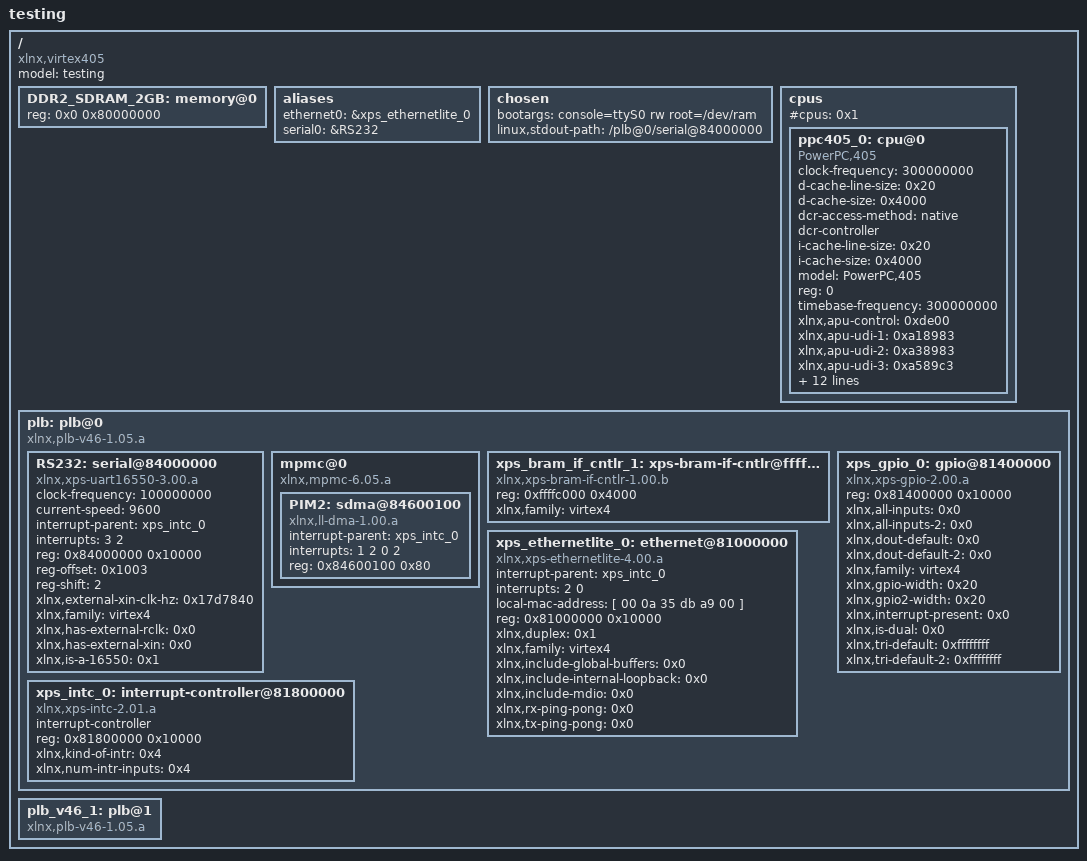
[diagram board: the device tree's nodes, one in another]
/*
 * Device Tree Generator version: 1.3
 *
 * (C) Copyright 2007-2008 Xilinx, Inc.
 * (C) Copyright 2007-2009 Michal Simek
 *
 * Michal SIMEK <monstr@monstr.eu>
 *
 * This program is free software; you can redistribute it and/or
 * modify it under the terms of the GNU General Public License as
 * published by the Free Software Foundation; either version 2 of
 * the License, or (at your option) any later version.
 *
 * This program is distributed in the hope that it will be useful,
 * but WITHOUT ANY WARRANTY; without even the implied warranty of
 * MERCHANTABILITY or FITNESS FOR A PARTICULAR PURPOSE. See the
 * GNU General Public License for more details.
 *
 * You should have received a copy of the GNU General Public License
 * along with this program; if not, write to the Free Software
 * Foundation, Inc., 59 Temple Place, Suite 330, Boston,
 * MA 02111-1307 USA
 *
 * CAUTION: This file is automatically generated by libgen.
 * Version: Xilinx EDK 13.3 EDK_O.76xd
 *
 * XPS project directory: device-tree_bsp_2
 */

/dts-v1/;
/ {
	#address-cells = <1>;
	#size-cells = <1>;
	compatible = "xlnx,virtex405", "xlnx,virtex";
	model = "testing";
	DDR2_SDRAM_2GB: memory@0 {
		device_type = "memory";
		reg = < 0x0 0x80000000 >;
	} ;
	aliases {
		ethernet0 = &xps_ethernetlite_0;
		serial0 = &RS232;
	} ;
	chosen {
		bootargs = "console=ttyS0 rw root=/dev/ram";
		linux,stdout-path = "/plb@0/serial@84000000";
	} ;
	cpus {
		#address-cells = <1>;
		#cpus = <0x1>;
		#size-cells = <0>;
		ppc405_0: cpu@0 {
			clock-frequency = <300000000>;
			compatible = "PowerPC,405", "ibm,ppc405";
			d-cache-line-size = <0x20>;
			d-cache-size = <0x4000>;
			dcr-access-method = "native";
			dcr-controller ;
			device_type = "cpu";
			i-cache-line-size = <0x20>;
			i-cache-size = <0x4000>;
			model = "PowerPC,405";
			reg = <0>;
			timebase-frequency = <300000000>;
			xlnx,apu-control = <0xde00>;
			xlnx,apu-udi-1 = <0xa18983>;
			xlnx,apu-udi-2 = <0xa38983>;
			xlnx,apu-udi-3 = <0xa589c3>;
			xlnx,apu-udi-4 = <0xa789c3>;
			xlnx,apu-udi-5 = <0xa98c03>;
			xlnx,apu-udi-6 = <0xab8c03>;
			xlnx,apu-udi-7 = <0xad8c43>;
			xlnx,apu-udi-8 = <0xaf8c43>;
			xlnx,deterministic-mult = <0x0>;
			xlnx,disable-operand-forwarding = <0x1>;
			xlnx,fastest-plb-clock = "DPLB0";
			xlnx,generate-plb-timespecs = <0x1>;
			xlnx,mmu-enable = <0x1>;
			xlnx,pvr-high = <0x0>;
			xlnx,pvr-low = <0x0>;
		} ;
	} ;
	plb: plb@0 {
		#address-cells = <1>;
		#size-cells = <1>;
		compatible = "xlnx,plb-v46-1.05.a", "xlnx,plb-v46-1.00.a", "simple-bus";
		ranges ;
		RS232: serial@84000000 {
			clock-frequency = <100000000>;
			compatible = "xlnx,xps-uart16550-3.00.a", "ns16550";
			current-speed = <9600>;
			device_type = "serial";
			interrupt-parent = <&xps_intc_0>;
			interrupts = < 3 2 >;
			reg = < 0x84000000 0x10000 >;
			reg-offset = <0x1003>;
			reg-shift = <2>;
			xlnx,external-xin-clk-hz = <0x17d7840>;
			xlnx,family = "virtex4";
			xlnx,has-external-rclk = <0x0>;
			xlnx,has-external-xin = <0x0>;
			xlnx,is-a-16550 = <0x1>;
		} ;
		mpmc@0 {
			#address-cells = <1>;
			#size-cells = <1>;
			compatible = "xlnx,mpmc-6.05.a";
			ranges ;
			PIM2: sdma@84600100 {
				compatible = "xlnx,ll-dma-1.00.a";
				interrupt-parent = <&xps_intc_0>;
				interrupts = < 1 2 0 2 >;
				reg = < 0x84600100 0x80 >;
			} ;
		} ;
		xps_bram_if_cntlr_1: xps-bram-if-cntlr@ffffc000 {
			compatible = "xlnx,xps-bram-if-cntlr-1.00.b", "xlnx,xps-bram-if-cntlr-1.00.a";
			reg = < 0xffffc000 0x4000 >;
			xlnx,family = "virtex4";
		} ;
		xps_ethernetlite_0: ethernet@81000000 {
			compatible = "xlnx,xps-ethernetlite-4.00.a", "xlnx,xps-ethernetlite-1.00.a";
			device_type = "network";
			interrupt-parent = <&xps_intc_0>;
			interrupts = < 2 0 >;
			local-mac-address = [ 00 0a 35 db a9 00 ];
			reg = < 0x81000000 0x10000 >;
			xlnx,duplex = <0x1>;
			xlnx,family = "virtex4";
			xlnx,include-global-buffers = <0x0>;
			xlnx,include-internal-loopback = <0x0>;
			xlnx,include-mdio = <0x0>;
			xlnx,rx-ping-pong = <0x0>;
			xlnx,tx-ping-pong = <0x0>;
		} ;
		xps_gpio_0: gpio@81400000 {
			compatible = "xlnx,xps-gpio-2.00.a", "xlnx,xps-gpio-1.00.a";
			reg = < 0x81400000 0x10000 >;
			xlnx,all-inputs = <0x0>;
			xlnx,all-inputs-2 = <0x0>;
			xlnx,dout-default = <0x0>;
			xlnx,dout-default-2 = <0x0>;
			xlnx,family = "virtex4";
			xlnx,gpio-width = <0x20>;
			xlnx,gpio2-width = <0x20>;
			xlnx,interrupt-present = <0x0>;
			xlnx,is-dual = <0x0>;
			xlnx,tri-default = <0xffffffff>;
			xlnx,tri-default-2 = <0xffffffff>;
		} ;
		xps_intc_0: interrupt-controller@81800000 {
			#interrupt-cells = <0x2>;
			compatible = "xlnx,xps-intc-2.01.a", "xlnx,xps-intc-1.00.a";
			interrupt-controller ;
			reg = < 0x81800000 0x10000 >;
			xlnx,kind-of-intr = <0x4>;
			xlnx,num-intr-inputs = <0x4>;
		} ;
	} ;
	plb_v46_1: plb@1 {
		#address-cells = <1>;
		#size-cells = <1>;
		compatible = "xlnx,plb-v46-1.05.a", "xlnx,plb-v46-1.00.a", "simple-bus";
		ranges ;
	} ;
} ;
